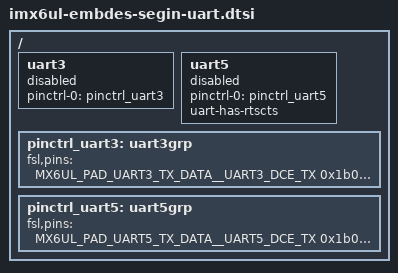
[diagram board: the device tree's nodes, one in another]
/* Vikneshwar embdes segin uart and i2c */

#include "imx6ul.dtsi"

/ {



uart3 {
        pinctrl-names = "default";
        pinctrl-0 = <&pinctrl_uart3>;
       /* uart-has-rtscts; */
        status = "disabled";
};

uart5 {
        pinctrl-names = "default";
        pinctrl-0 = <&pinctrl_uart5>;
        uart-has-rtscts; 
        status = "disabled";
};

/*
i2c2 {
	clock_frequency = <100000>;
	pinctrl-names = "default";
	pinctrl-0 = <&pinctrl_i2c2>;
	status = "okay";
};

*/

/*
 pinctrl_i2c2: i2c2grp {
		fsl,pins = <
			MX6UL_PAD_CSI_HSYNC__I2C2_SCL 0x4001b8b0
			MX6UL_PAD_CSI_VSYNC__I2C2_SDA 0x4001b8b0
		>;
	};

 */ 

 pinctrl_uart3: uart3grp {
                fsl,pins = <
                        MX6UL_PAD_UART3_TX_DATA__UART3_DCE_TX   0x1b0b1
                        MX6UL_PAD_UART3_RX_DATA__UART3_DCE_RX   0x1b0b1                      
                                                
                >;
        };


 pinctrl_uart5: uart5grp {
                fsl,pins = <
                        MX6UL_PAD_UART5_TX_DATA__UART5_DCE_TX   0x1b0b1
                        MX6UL_PAD_UART5_RX_DATA__UART5_DCE_RX   0x1b0b1
                        MX6UL_PAD_GPIO1_IO08__UART5_DCE_RTS     0x1b0b1
                        MX6UL_PAD_GPIO1_IO09__UART5_DCE_CTS     0x1b0b1
                >;
        };

 

};





















